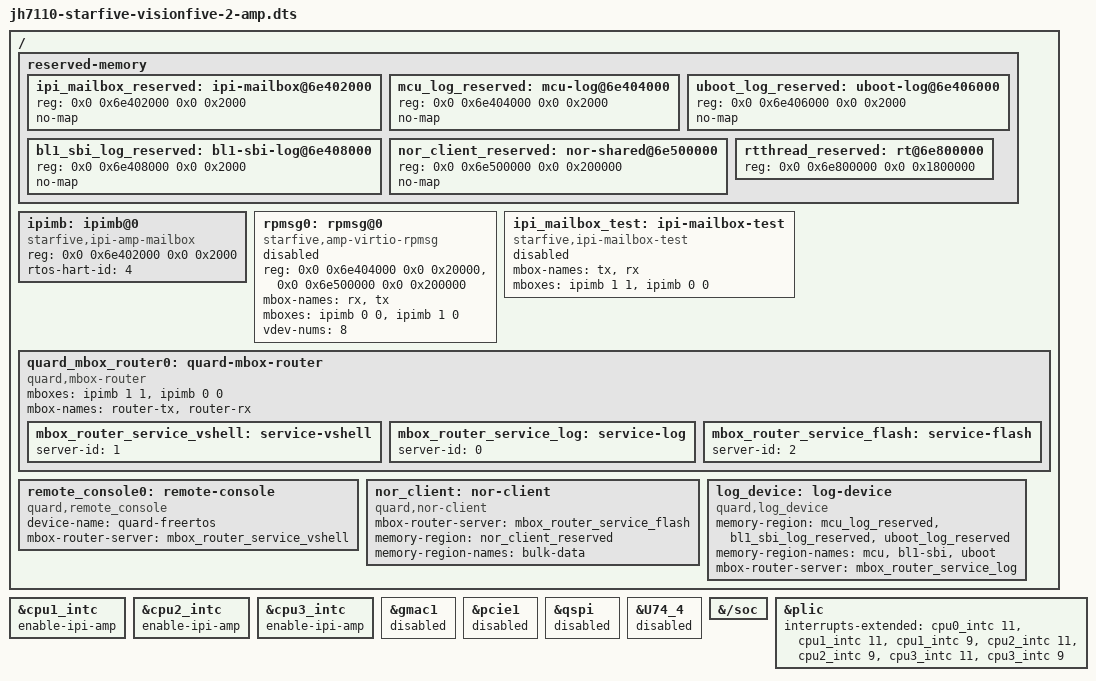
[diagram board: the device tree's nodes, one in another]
// SPDX-License-Identifier: GPL-2.0 OR MIT
/*
 * Copyright (C) 2022 StarFive Technology Co., Ltd.
 */

/dts-v1/;
#include "jh7110-starfive-visionfive-2-v1.3b.dts"

/ {
	reserved-memory {
		/* Shared IPI mailbox transport: 2 channels in the first 64 bytes. */
		ipi_mailbox_reserved: ipi-mailbox@6e402000 {
			reg = <0x0 0x6e402000 0x0 0x2000>;
			no-map;
		};

		mcu_log_reserved: mcu-log@6e404000 {
			reg = <0x0 0x6e404000 0x0 0x2000>;
			no-map;
		};

		uboot_log_reserved: uboot-log@6e406000 {
			reg = <0x0 0x6e406000 0x0 0x2000>;
			no-map;
		};

		bl1_sbi_log_reserved: bl1-sbi-log@6e408000 {
			reg = <0x0 0x6e408000 0x0 0x2000>;
			no-map;
		};

		nor_client_reserved: nor-shared@6e500000 {
			reg = <0x0 0x6e500000 0x0 0x200000>;
			no-map;
		};

		rtthread_reserved: rt@6e800000 {
			reg = <0x0 0x6e800000 0x0 0x1800000>;
		};
	};

	ipimb: ipimb@0 {
		compatible = "starfive,ipi-amp-mailbox";
		reg = <0x0 0x6e402000 0x0 0x2000>;
		#mbox-cells = <2>;
		rtos-hart-id = <4>;
		status = "okay";
	};

	rpmsg0: rpmsg@0 {
		compatible = "starfive,amp-virtio-rpmsg";
		reg = <0x0 0x6e404000 0x0 0x20000>,
			<0x0 0x6e500000 0x0 0x200000>;
		mbox-names = "rx", "tx";
		mboxes = <&ipimb 0 0>, <&ipimb 1 0>;
		vdev-nums = <8>;
		status = "disabled";
	};

	/* The production path below owns both channels. Keep the direct test
	 * disabled so it cannot request the same mailbox channels.
	 */
	ipi_mailbox_test: ipi-mailbox-test {
		compatible = "starfive,ipi-mailbox-test";
		mbox-names = "tx", "rx";
		mboxes = <&ipimb 1 1>, <&ipimb 0 0>;
		status = "disabled";
	};

	quard_mbox_router0: quard-mbox-router {
		compatible = "quard,mbox-router";
		/* Linux TX -> FreeRTOS channel 1; FreeRTOS TX -> Linux channel 0. */
		mboxes = <&ipimb 1 1>, <&ipimb 0 0>;
		mbox-names = "router-tx", "router-rx";
		status = "okay";

		mbox_router_service_vshell: service-vshell {
			server-id = <1>;
		};

		mbox_router_service_log: service-log {
			server-id = <0>;
		};

		mbox_router_service_flash: service-flash {
			server-id = <2>;
		};
	};

	remote_console0: remote-console {
		compatible = "quard,remote_console";
		device-name = "quard-freertos";
		mbox-router-server = <&mbox_router_service_vshell>;
		status = "okay";
	};

	nor_client: nor-client {
		compatible = "quard,nor-client";
		mbox-router-server = <&mbox_router_service_flash>;
		memory-region = <&nor_client_reserved>;
		memory-region-names = "bulk-data";
		status = "okay";
	};

	log_device: log-device {
		compatible = "quard,log_device";
		memory-region = <&mcu_log_reserved>,
				<&bl1_sbi_log_reserved>,
				<&uboot_log_reserved>;
		memory-region-names = "mcu", "bl1-sbi", "uboot";
		mbox-router-server = <&mbox_router_service_log>;
		status = "okay";
	};
};

&cpu1_intc {
	enable-ipi-amp;
};

&cpu2_intc {
	enable-ipi-amp;
};

&cpu3_intc {
	enable-ipi-amp;
};

&gmac1 {
	status = "disabled";
};

&pcie1 {
	status = "disabled";
};

/* Cadence QSPI and the onboard SPI NOR are owned by hart4 FreeRTOS. */
&qspi {
	status = "disabled";
};

&U74_4 {
	status = "disabled";
};

/* UART2 (0x10020000, IRQ34) is owned by the FreeRTOS AMP image. */
&{/soc} {
	/delete-node/ serial@10020000;
};

&rpmsg0 {
	status = "disabled";
};

/*
 * Hart4 is reserved for the FreeRTOS AMP image. Do not expose its PLIC
 * machine/supervisor contexts to Linux, otherwise the Linux PLIC driver may
 * reconfigure the context used by the RTOS.
 */
&plic {
	interrupts-extended = <&cpu0_intc 11>,
				      <&cpu1_intc 11>, <&cpu1_intc 9>,
				      <&cpu2_intc 11>, <&cpu2_intc 9>,
				      <&cpu3_intc 11>, <&cpu3_intc 9>;
};
